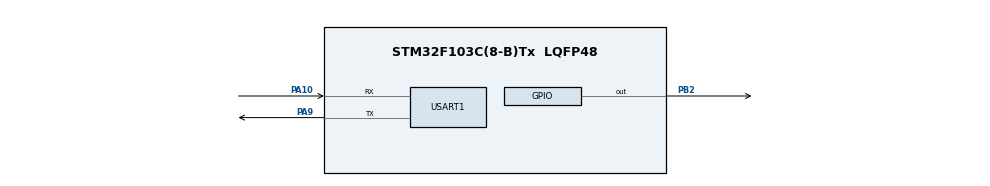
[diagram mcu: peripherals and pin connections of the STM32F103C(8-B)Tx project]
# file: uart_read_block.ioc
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Mcu.Family=STM32F1
Mcu.Name=STM32F103C(8-B)Tx
Mcu.Package=LQFP48
NVIC.PriorityGroup=NVIC_PRIORITYGROUP_4
NVIC.USART1_IRQn=true\:1\:0\:true\:false\:true\:true\:true\:true
PA10.Mode=Asynchronous
PA10.Signal=USART1_RX
PA13.Mode=Serial_Wire
PA13.Signal=SYS_JTMS-SWDIO
PA14.Mode=Serial_Wire
PA14.Signal=SYS_JTCK-SWCLK
PA9.Mode=Asynchronous
PA9.Signal=USART1_TX
PB2.Signal=GPIO_Output
ProjectManager.HeapSize=0x3000
ProjectManager.StackSize=0x1000
ProjectManager.TargetToolchain=STM32CubeIDE
RCC.APB1Freq_Value=8000000
RCC.APB2Freq_Value=8000000
USART1.VirtualMode=VM_ASYNC
board=custom

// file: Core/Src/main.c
/* USER CODE BEGIN Header */
/**
 Базовое чтение данных по UART.
 Для приема сообщений имеется функция HAL_UART_Receive,
аналогичная HAL_UART_Transmit. Поскольку эта функция требует
знать заранее, сколько данных необходимо принять, воспользуемся более низкоуровневыми функциями.

 Программа считывает символы по UART и отправляет их обратно. Для поверки наличия пришедшего
  символа используется макрос
__HAL_UART_GET_FLAG:
has_data_flag = __HAL_UART_GET_FLAG(&huart2, UART_FLAG_RXNE);
Считывание пришедшего байта происходит из регистра UART следующим образом:
sym = huart2.Instance->RDR;
Если считанный байт кодирует символ с графическим представлением, он выводится обратно
 с помощью функции HAL_UART_
Transmit без изменений, иначе выводится его код в шестнадцатеричной форме.

 */
/**
  ******************************************************************************
  * @file           : main.c
  * @brief          : Main program body
  ******************************************************************************
  * @attention
  *
  * Copyright (c) 2025 STMicroelectronics.
  * All rights reserved.
  *
  * This software is licensed under terms that can be found in the LICENSE file
  * in the root directory of this software component.
  * If no LICENSE file comes with this software, it is provided AS-IS.
  *
  ******************************************************************************
  */
/* USER CODE END Header */
#include "main.h"

/* USER CODE BEGIN Includes */
#include <string.h>
#include <stdio.h>
#include <ctype.h>
/* USER CODE END Includes */

UART_HandleTypeDef huart1;

void SystemClock_Config(void);
static void MX_GPIO_Init(void);
static void MX_USART1_UART_Init(void);

int main(void)
{

  /* MCU Configuration--------------------------------------------------------*/

  /* Reset of all peripherals, Initializes the Flash interface and the Systick. */
  HAL_Init();

  /* Configure the system clock */
  SystemClock_Config();

  /* Initialize all configured peripherals */
  MX_GPIO_Init();
  MX_USART1_UART_Init();
  /* USER CODE BEGIN 2 */
  const char *start_message = "-- Start --\n";
  char echo_message[32];
  int has_data_flag;
  char sym;
  HAL_UART_Transmit(&huart1, (uint8_t*) (start_message),
  strlen(start_message), HAL_MAX_DELAY);
  /* USER CODE END 2 */

  /* Infinite loop */
  /* USER CODE BEGIN WHILE */
  while (1)
  {
	  // check
	  has_data_flag = __HAL_UART_GET_FLAG(&huart1, UART_FLAG_RXNE);
	  if (has_data_flag) {
		  // read data
		  sym = huart1.Instance->DR;
		  // prepare echo message
		  if (isgraph(sym)) {
			  // show printable character as is
			  sprintf(echo_message, "\necho: %c\n", sym);
			  HAL_UART_Transmit(&huart1, (uint8_t*) (echo_message), strlen(echo_message), HAL_MAX_DELAY);
		  } else {
			  // show hexadecimal code of the non printable character
			  sprintf(echo_message, "\necho: 0x%02X\n", sym);
			  HAL_UART_Transmit(&huart1, (uint8_t*)(echo_message), strlen(echo_message), HAL_MAX_DELAY);
		  }
	  }
	  HAL_GPIO_TogglePin(GPIOB, GPIO_PIN_2);
	  HAL_Delay(500);
    /* USER CODE END WHILE */

  }
}

void SystemClock_Config(void)
{
  RCC_OscInitTypeDef RCC_OscInitStruct = {0};
  RCC_ClkInitTypeDef RCC_ClkInitStruct = {0};

  /** Initializes the RCC Oscillators according to the specified parameters
  * in the RCC_OscInitTypeDef structure.
  */
  RCC_OscInitStruct.OscillatorType = RCC_OSCILLATORTYPE_HSI;
  RCC_OscInitStruct.HSIState = RCC_HSI_ON;
  RCC_OscInitStruct.HSICalibrationValue = RCC_HSICALIBRATION_DEFAULT;
  RCC_OscInitStruct.PLL.PLLState = RCC_PLL_NONE;
  if (HAL_RCC_OscConfig(&RCC_OscInitStruct) != HAL_OK)
  {
    Error_Handler();
  }

  /** Initializes the CPU, AHB and APB buses clocks
  */
  RCC_ClkInitStruct.ClockType = RCC_CLOCKTYPE_HCLK|RCC_CLOCKTYPE_SYSCLK
                              |RCC_CLOCKTYPE_PCLK1|RCC_CLOCKTYPE_PCLK2;
  RCC_ClkInitStruct.SYSCLKSource = RCC_SYSCLKSOURCE_HSI;
  RCC_ClkInitStruct.AHBCLKDivider = RCC_SYSCLK_DIV1;
  RCC_ClkInitStruct.APB1CLKDivider = RCC_HCLK_DIV1;
  RCC_ClkInitStruct.APB2CLKDivider = RCC_HCLK_DIV1;

  if (HAL_RCC_ClockConfig(&RCC_ClkInitStruct, FLASH_LATENCY_0) != HAL_OK)
  {
    Error_Handler();
  }
}

static void MX_USART1_UART_Init(void)
{

  huart1.Instance = USART1;
  huart1.Init.BaudRate = 115200;
  huart1.Init.WordLength = UART_WORDLENGTH_8B;
  huart1.Init.StopBits = UART_STOPBITS_1;
  huart1.Init.Parity = UART_PARITY_NONE;
  huart1.Init.Mode = UART_MODE_TX_RX;
  huart1.Init.HwFlowCtl = UART_HWCONTROL_NONE;
  huart1.Init.OverSampling = UART_OVERSAMPLING_16;
  if (HAL_UART_Init(&huart1) != HAL_OK)
  {
    Error_Handler();
  }

}

static void MX_GPIO_Init(void)
{
  GPIO_InitTypeDef GPIO_InitStruct = {0};

  /* GPIO Ports Clock Enable */
  __HAL_RCC_GPIOB_CLK_ENABLE();
  __HAL_RCC_GPIOA_CLK_ENABLE();

  /*Configure GPIO pin Output Level */
  HAL_GPIO_WritePin(GPIOB, GPIO_PIN_2, GPIO_PIN_RESET);

  /*Configure GPIO pin : PB2 */
  GPIO_InitStruct.Pin = GPIO_PIN_2;
  GPIO_InitStruct.Mode = GPIO_MODE_OUTPUT_PP;
  GPIO_InitStruct.Pull = GPIO_NOPULL;
  GPIO_InitStruct.Speed = GPIO_SPEED_FREQ_LOW;
  HAL_GPIO_Init(GPIOB, &GPIO_InitStruct);

}

void Error_Handler(void)
{
  __disable_irq();
  while (1)
  {
  }
}
